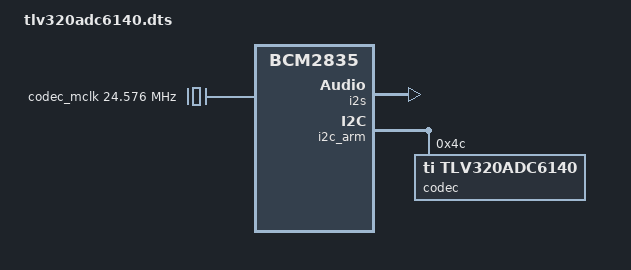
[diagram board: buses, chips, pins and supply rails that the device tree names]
/dts-v1/;
/plugin/;


/ {

    compatible = "brcm,bcm2835";


    fragment@0 {
        target = <&i2s>;
        __overlay__ {
            status = "okay";
        };
    };

    fragment@1 {
        target = <&i2c_arm>;
        __overlay__ {
            #address-cells = <1>;
            #size-cells = <0>;
            status = "okay";
            codec: codec@4c {
                #sound-dai-cells = <0>;
                compatible = "ti,tlv320adc6140";
                reg = <0x4c>;
                ti,vref-sourde = <0>;
                ti,mic-bias-source = <0>;
                ti,gpio-config = <10 2>;
                ti,pdm-edge-select = <0 1 0 1>;
                ti,gpi-config = <0 0 0 0>;
                ti,gpo-config-1 = <0 0>;
                ti,gpo-config-2 = <0 0>;

//		reset-gpios = <&gpio 4 0>;


            };
        };
    };



    fragment@2 {
                target-path="/";
                __overlay__ {
                        codec_mclk:codec-mclk {
                                compatible = "fixed-clock";
                                #clock-cells = <0>;
                                clock-frequency = <24576000>;
                         };
               };
    };
    

    fragment@3 {
        target = <&sound>;
        __overlay__ {
            compatible = "simple-audio-card";
            i2s-controller = <&i2s>;
            status = "okay";

            simple-audio-card,format = "i2s";
            simple-audio-card,name = "ADC6140";
            simple-audio-card,bitclock-master = <&sound_master>;
            simple-audio-card,frame-master = <&sound_master>;

            simple-audio-card,cpu {
                sound-dai = <&i2s>;
            };
            sound_master: simple-audio-card,codec {
                sound-dai = <&codec>;
                clocks = <&codec_mclk>;
            };
        };
    };


};

